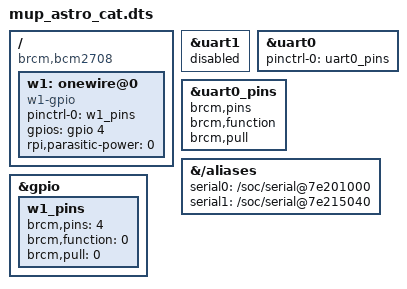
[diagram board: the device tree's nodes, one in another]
/dts-v1/;
/plugin/;

/ {
	compatible = "brcm,bcm2708";

	// pi3-disable-bt-overlay
	fragment@0 {
		target = <&uart1>;
		__overlay__ {
			status = "disabled";
		};
	};

	fragment@1 {
		target = <&uart0>;
		__overlay__ {
			pinctrl-names = "default";
			pinctrl-0 = <&uart0_pins>;
			status = "okay";
		};
	};

	fragment@2 {
		target = <&uart0_pins>;
		__overlay__ {
			brcm,pins;
			brcm,function;
			brcm,pull;
		};
	};

	fragment@3 {
		target-path = "/aliases";
		__overlay__ {
			serial0 = "/soc/serial@7e201000";
			serial1 = "/soc/serial@7e215040";
		};
	};

	// w1-gpio-overlay
	fragment@4 {
		target-path = "/";
		__overlay__ {

			w1: onewire@0 {
				compatible = "w1-gpio";
				pinctrl-names = "default";
				pinctrl-0 = <&w1_pins>;
				gpios = <&gpio 4 0>;
				rpi,parasitic-power = <0>;
				status = "okay";
			};
		};
	};

	fragment@5 {
		target = <&gpio>;
		__overlay__ {
			w1_pins: w1_pins {
				brcm,pins = <4>;
				brcm,function = <0>; // in (initially)
				brcm,pull = <0>; // off
			};
		};
	};

	__overrides__ {
		gpiopin =       <&w1>,"gpios:4",
				<&w1_pins>,"brcm,pins:0";
		pullup =        <&w1>,"rpi,parasitic-power:0";
	};

};
